# SKEAZN84 register map
Vendor: Freescale Semiconductor, Inc.; File version: 1.6
SKEAZN84 Freescale Microcontroller
CPU: CM0PLUS r0p0, little endian, no MPU, no FPU, 0x2 interrupt priority bits, 0x0 interrupts
Registers are 32-bit, read-write, reset 0x0 unless marked. A register's access mark holds for its fields unless they carry their own. Offsets are from the block's base; lines under a group give offsets from that group; [hi:lo] are bit positions; {n}, {i} and the like mark numbered series; 'fields as' and 'values as' point back to an identical list; <NAME> marks a mode.

## Memory map
0x00000400 FTMRE_FlashConfig size 0x10 — Flash configuration field
0x40020000 FTMRE blocks up to offset 0x10 — Flash Memory
0x40031000 IRQ size 0x1 — Interrupt
0x40032000 CRC size 0xC — Cyclic Redundancy Check
0x40033000 PWT size 0x8 — Pulse Width Timer
0x40037000 PIT size 0x120 — Periodic Interrupt Timer
0x40038000 FTM0 size 0x1C — FlexTimer Module
0x4003A000 FTM2 size 0x9C — FlexTimer Module
0x4003B000 ADC size 0x20 — Analog-to-digital converter
0x4003D000 RTC size 0xC — Real-time counter
0x40048000 SIM size 0x20 — System Integration Module
0x40049000 PORT size 0x10 — Port control and interrupts
0x40052000 WDOG size 0x8 — Watchdog timer
0x40064000 ICS size 0x5 — Clock management
0x40065000 OSC size 0x1 — Oscillator
0x40066000 I2C0 size 0xC — Inter-Integrated Circuit
0x4006A000 UART0 size 0x8 — Universal Asynchronous Receiver/Transmitter (UART)
0x40073000 ACMP0 size 0x4 — Analog comparator
0x40074000 ACMP1 size 0x4 — Analog comparator
0x40076000 SPI0 size 0x8 — Serial Peripheral Interface
0x40079000 KBI0 size 0x3 — Keyboard interrupts
0x4007A000 KBI1 size 0x3 — Keyboard interrupts
0x4007D000 PMC size 0x2 — Power management
0x400FF000 GPIOA size 0x1C — General Purpose Input/Output
0xE000E000 SystemControl blocks up to offset 0xD34 — System Control Registers
0xE000E010 SysTick size 0x10 — System timer
0xE000E100 NVIC size 0x320 — Nested Vectored Interrupt Controller
0xF0002000 ROM size 0x1000 — System ROM
0xF0003000 MCM blocks up to offset 0x10 — Core Platform Miscellaneous Control Module
0xF8000000 FGPIOA size 0x1C — General Purpose Input/Output

## Interrupts
5 FTMRE
6 LVD_LVW (PMC)
7 IRQ
8 I2C0
10 SPI0
12 UART0
15 ADC0 (ADC)
16 ACMP0
17 FTM0
19 FTM2
20 RTC
21 ACMP1
22 PIT_CH0 (PIT)
23 PIT_CH1 (PIT)
24 KBI0
25 KBI1
27 ICS
28 WDOG_EWM (WDOG)
29 PWT

## FTMRE_FlashConfig — Flash configuration field
Base 0x00000400; register names take the prefix NV_
{0x0+i} BACKKEY{i} 8-bit ro reset 0xFF (i=0..7) — Backdoor Comparison Key {i}
  [7:0] KEY — Backdoor Comparison Key.
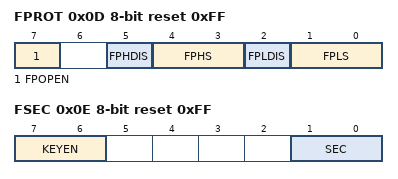
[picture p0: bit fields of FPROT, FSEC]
0x0D FPROT 8-bit ro reset 0xFF — Non-volatile P-Flash Protection Register
  [7] FPOPEN
    0=FPHDIS and FPLDIS bits define unprotected address ranges as specified by the corresponding FPHS and FPLS bits FPROT1.1; 1=FPHDIS and FPLDIS bits enable protection for the address range specified by the corresponding FPHS and FPLS bits
  [5] FPHDIS
    0=Protection/Unprotection enabled; 1=Protection/Unprotection disabled
  [4:3] FPHS
    0=Address range: 0x00_7C00-0x00_7FFF; protected size: 1 KB; 1=Address range: 0x00_7800-0x00_7FFF; protected size: 2 KB; 2=Address range: 0x00_7000-0x00_7FFF; protected size: 4 KB; 3=Address range: 0x00_6000-0x00_7FFF; protected size: 8 KB
  [2] FPLDIS
    values as FPHDIS
  [1:0] FPLS
    0=Address range: 0x00_0000-0x00_07FF; protected size: 2 KB; 1=Address range: 0x00_0000-0x00_0FFF; protected size: 4 KB; 2=Address range: 0x00_0000-0x00_1FFF; protected size: 8 KB; 3=Address range: 0x00_0000-0x00_3FFF; protected size: 16 KB
0x0E FSEC 8-bit ro reset 0xFF — Non-volatile Flash Security Register
  [7:6] KEYEN — Backdoor Key Security Enable
    2=Backdoor key access enabled; 3=Backdoor key access disabled
  [1:0] SEC — Flash Security
    2=MCU security status is unsecure; 3=MCU security status is secure
0x0F FOPT 8-bit ro reset 0xFF — Non-volatile Flash Option Register

## FTMRE — Flash Memory
Base 0x40020000; register names take the prefix FTMRE_
0x01 FCCOBIX 8-bit — Flash CCOB Index Register
  [2:0] CCOBIX — Common Command Register Index
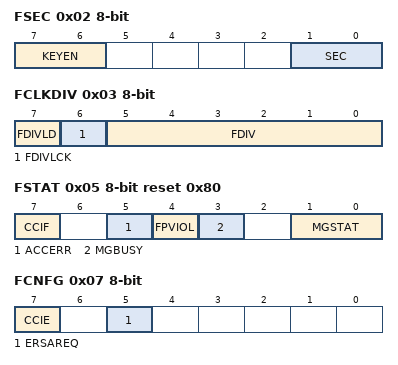
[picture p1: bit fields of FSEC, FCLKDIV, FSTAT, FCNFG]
0x02 FSEC 8-bit ro reset not defined — Flash Security Register
  [7:6] KEYEN — Backdoor Key Security Enable Bits
    0=Disabled; 1=Disabled; 2=Enabled; 3=Disabled
  [1:0] SEC — Flash Security Bits
    0=Secured; 1=Secured; 2=Unsecured; 3=Secured
0x03 FCLKDIV 8-bit — Flash Clock Divider Register
  [7] FDIVLD ro — Clock Divider Loaded
    0=FCLKDIV register has not been written since the last reset; 1=FCLKDIV register has been written since the last reset
  [6] FDIVLCK — Clock Divider Locked
    0=FDIV field is open for writing; 1=FDIV value is locked and cannot be changed. After the lock bit is set high, only reset can clear this bit and restore writability to the FDIV field in user mode.
  [5:0] FDIV — Clock Divider Bits
0x05 FSTAT 8-bit reset 0x80 — Flash Status Register
  [7] CCIF — Command Complete Interrupt Flag
    0=Flash command is in progress; 1=Flash command has completed
  [5] ACCERR — Flash Access Error Flag
    0=No access error is detected; 1=Access error is detected
  [4] FPVIOL — Flash Protection Violation Flag
    0=No protection violation is detected; 1=Protection violation is detected
  [3] MGBUSY ro — Memory Controller Busy Flag
    0=Memory controller is idle; 1=Memory controller is busy executing a flash command (CCIF = 0)
  [1:0] MGSTAT ro — Memory Controller Command Completion Status Flag
0x07 FCNFG 8-bit — Flash Configuration Register
  [7] CCIE — Command Complete Interrupt Enable
    0=Command complete interrupt is disabled; 1=An interrupt will be requested whenever the CCIF flag in the FSTAT register is set
  [5] ERSAREQ ro — Debugger Mass Erase Request
    0=No request or request complete; 1=Request to run the Erase All Blocks command verify the erased state program the security byte in the Flash Configuration Field to the unsecure state release MCU security by setting FSEC[SEC] to the unsecure state
0x08 FCCOBLO 8-bit — Flash Common Command Object Register: Low
  [7:0] CCOB — Common Command Object Bit 7:0
0x09 FCCOBHI 8-bit — Flash Common Command Object Register:High
  [7:0] CCOB — Common Command Object Bit 15:8
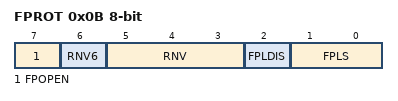
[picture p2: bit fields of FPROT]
0x0B FPROT 8-bit (reset mask 0x38) — Flash Protection Register
  [7] FPOPEN — Flash Protection Operation Enable
    0=When FPOPEN is clear, the FPLDIS field defines unprotected address ranges as specified by the corresponding FPLS field; 1=When FPOPEN is set, the FPLDIS field enables protection for the address range specified by the corresponding FPLS field
  [6] RNV6 ro — Reserved Nonvolatile Bit
  [5:3] RNV ro — Reserved Nonvolatile Bit
  [2] FPLDIS — Flash Protection Lower Address Range Disable
    0=Protection/Unprotection enabled; 1=Protection/Unprotection disabled
  [1:0] FPLS — Flash Protection Lower Address Size
0x0F FOPT 8-bit ro reset not defined — Flash Option Register
  [7:0] NV — Nonvolatile Bits
